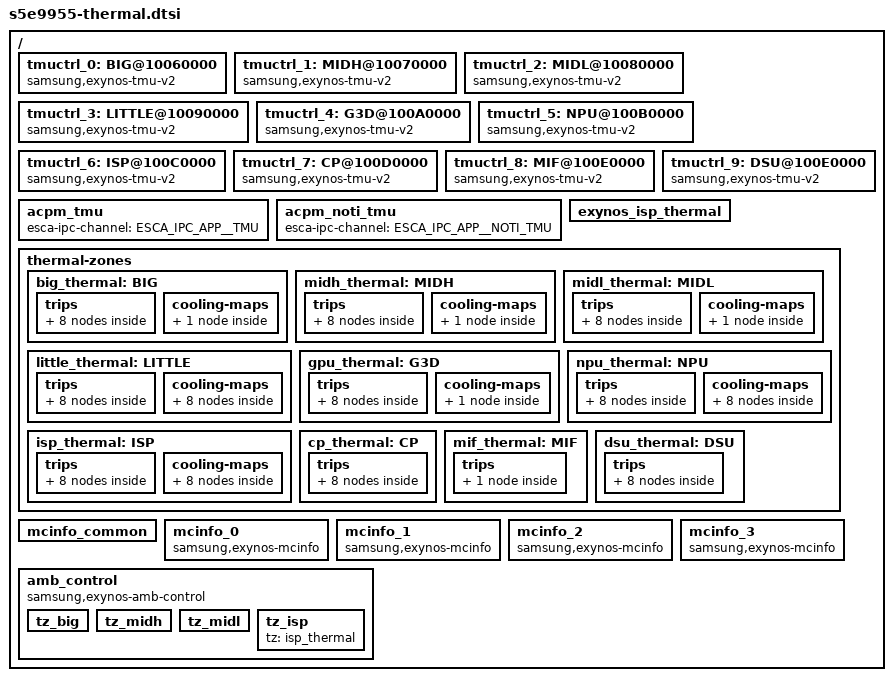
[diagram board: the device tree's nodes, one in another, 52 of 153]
/*
 * SAMSUNG EXYNOS9955 SoC DVFS Manager device tree source
 *
 * Copyright (c) 2024 Samsung Electronics Co., Ltd.
 *		http://www.samsung.com
 *
 * SAMSUNG EXYNOS9955 SoC device nodes are listed in this file.
 * EXYNOS based board files can include this file and provide
 * values for board specfic bindings.
 *
 * This program is free software; you can redistribute it and/or modify
 * it under the terms of the GNU General Public License version 2 as
 * published by the Free Software Foundation.
 */

/ {
	tmuctrl_0: BIG@10060000 {
		compatible = "samsung,exynos-tmu-v2";
		//reg = <0x0 0x10060000 0x800>;
		//interrupts = <GIC_SPI INTREQ__TMU_TMU_0 IRQ_TYPE_LEVEL_HIGH>;
		tmu_name = "BIG";
		id = <0>;
		hotplug_enable = <1>;
		hotplug_in_threshold = <91>;
		hotplug_out_threshold = <96>;
		cpu_domain = "9";
		#thermal-sensor-cells = <0>;
		//cal_id = <ACPM_DVFS_CPUCL3>;

		use-pi-thermal;
		polling_delay_on = <4>;
		polling_delay_off = <1000>;
		k_po = <0>;
		k_pu = <0>;
		k_i = <0>;
		i_max = <0>;
		integral_cutoff = <0>;
		sustainable_power = <0>;

		thermal_status_level = <80000 85000 90000>;
	};

	tmuctrl_1: MIDH@10070000 {
		compatible = "samsung,exynos-tmu-v2";
		//reg = <0x0 0x10070000 0x800>;
		//interrupts = <GIC_SPI INTREQ__TMU_TMU_1 IRQ_TYPE_LEVEL_HIGH>;
		tmu_name = "MIDH";
		hotplug_enable = <1>;
		hotplug_in_threshold = <91>;
		hotplug_out_threshold = <96>;
		cpu_domain = "7-8";
		id = <1>;
		#thermal-sensor-cells = <0>;
		//cal_id = <ACPM_DVFS_CPUCL2>;

		use-pi-thermal;
		polling_delay_on = <10>;
		polling_delay_off = <1000>;
		k_po = <0>;
		k_pu = <0>;
		k_i = <0>;
		i_max = <0>;
		integral_cutoff = <0>;
		sustainable_power = <0>;
	};

	tmuctrl_2: MIDL@10080000 {
		compatible = "samsung,exynos-tmu-v2";
		//reg = <0x0 0x10070000 0x800>;
		//interrupts = <GIC_SPI INTREQ__TMU_TMU_1 IRQ_TYPE_LEVEL_HIGH>;
		tmu_name = "MIDL";
		hotplug_enable = <1>;
		hotplug_in_threshold = <91>;
		hotplug_out_threshold = <96>;
		cpu_domain = "2-6";
		id = <2>;
		#thermal-sensor-cells = <0>;
		//cal_id = <ACPM_DVFS_CPUCL1>;

		use-pi-thermal;
		polling_delay_on = <10>;
		polling_delay_off = <1000>;
		k_po = <0>;
		k_pu = <0>;
		k_i = <0>;
		i_max = <0>;
		integral_cutoff = <0>;
		sustainable_power = <0>;
	};

	tmuctrl_3: LITTLE@10090000 {
		compatible = "samsung,exynos-tmu-v2";
		//reg = <0x0 0x10060000 0x800>;
		//interrupts = <GIC_SPI INTREQ__TMU_TMU_0 IRQ_TYPE_LEVEL_HIGH>;
		tmu_name = "LITTLE";
		id = <3>;
		#thermal-sensor-cells = <0>;
		polling_delay_on = <20>;
		polling_delay_off = <1000>;
	};

	tmuctrl_4: G3D@100A0000 {
		compatible = "samsung,exynos-tmu-v2";
		//reg = <0x0 0x10090000 0x800>;
		//interrupts = <GIC_SPI INTREQ__TMU_TMU_3 IRQ_TYPE_LEVEL_HIGH>;
		tmu_name = "G3D";
		id = <4>;
		#thermal-sensor-cells = <0>;

		use-pi-thermal;
		polling_delay_on = <10>;
		polling_delay_off = <1000>;
		k_po = <0>;
		k_pu = <0>;
		k_i = <0>;
		i_max = <0>;
		integral_cutoff = <0>;
		sustainable_power = <0>;
	};

	tmuctrl_5: NPU@100B0000 {
		compatible = "samsung,exynos-tmu-v2";
		//reg = <0x0 0x10080000 0x800>;
		//interrupts = <GIC_SPI INTREQ__TMU_TMU_2 IRQ_TYPE_LEVEL_HIGH>;
		tmu_name = "NPU";
		id = <5>;
		#thermal-sensor-cells = <0>;
	};

	tmuctrl_6: ISP@100C0000 {
		compatible = "samsung,exynos-tmu-v2";
		//reg = <0x0 0x10080000 0x800>;
		//interrupts = <GIC_SPI INTREQ__TMU_TMU_2 IRQ_TYPE_LEVEL_HIGH>;
		tmu_name = "ISP";
		id = <6>;
		#thermal-sensor-cells = <0>;
	};

	tmuctrl_7: CP@100D0000 {
		compatible = "samsung,exynos-tmu-v2";
		//reg = <0x0 0x10090000 0x800>;
		//interrupts = <GIC_SPI INTREQ__TMU_TMU_3 IRQ_TYPE_LEVEL_HIGH>;
		tmu_name = "CP";
		id = <7>;
		#thermal-sensor-cells = <0>;
	};

	tmuctrl_8: MIF@100E0000 {
		compatible = "samsung,exynos-tmu-v2";
		//reg = <0x0 0x10080000 0x800>;
		//interrupts = <GIC_SPI INTREQ__TMU_TMU_2 IRQ_TYPE_LEVEL_HIGH>;
		tmu_name = "MIF";
		id = <8>;
		#thermal-sensor-cells = <0>;
	};

	tmuctrl_9: DSU@100E0000 {
		compatible = "samsung,exynos-tmu-v2";
		//reg = <0x0 0x10080000 0x800>;
		//interrupts = <GIC_SPI INTREQ__TMU_TMU_2 IRQ_TYPE_LEVEL_HIGH>;
		tmu_name = "DSU";
		id = <9>;
		#thermal-sensor-cells = <0>;
	};

	acpm_tmu {
		esca-ipc-channel = <ESCA_IPC_APP__TMU>;
	};

	acpm_noti_tmu {
		esca-ipc-channel = <ESCA_IPC_APP__NOTI_TMU>;
	};

	exynos_isp_thermal: exynos_isp_thermal {
		#cooling-cells = <2>; /* min followed by max */
	};

	thermal-zones {
		big_thermal: BIG {
			zone_name  = "BIG_THERMAL";
			polling-delay-passive = <0>;
			polling-delay = <0>;
			thermal-sensors = <&tmuctrl_0>;

			trips {
				big_cold: big-cold {
					temperature = <20000>;
					hysteresis = <5000>; /* millicelsius */
					type = "active";
				};
				big_switch_on: big-switch-on {
					temperature = <60000>; /* millicelsius */
					hysteresis = <2000>; /* millicelsius */
					type = "active";
				};
				big_control_temp: big-control-temp {
					temperature = <70000>; /* millicelsius */
					hysteresis = <5000>; /* millicelsius */
					type = "passive";
				};
				big_alert0: big-alert0 {
					temperature = <95000>; /* millicelsius */
					hysteresis = <5000>; /* millicelsius */
					type = "active";
				};
				big_alert1: big-alert1 {
					temperature = <100000>; /* millicelsius */
					hysteresis = <5000>; /* millicelsius */
					type = "passive";
				};
				big_alert2: big-alert2 {
					temperature = <105000>; /* millicelsius */
					hysteresis = <5000>; /* millicelsius */
					type = "passive";
				};
				big_alert3: big-alert3 {
					temperature = <110000>; /* millicelsius */
					hysteresis = <5000>; /* millicelsius */
					type = "active";
				};
				big_hot: big-hot {
					temperature = <115000>; /* millicelsius */
					hysteresis = <5000>; /* millicelsius */
					type = "hot";
				};
			};
			cooling-maps {
				map0 {
					trip = <&big_control_temp>;
					cooling-device = <&cpufreq_domain3 0 0>;
				};
			};
		};

		midh_thermal: MIDH {
			zone_name  = "MIDH_THERMAL";
			polling-delay-passive = <0>;
			polling-delay = <0>;
			thermal-sensors = <&tmuctrl_1>;

			trips {
				midh_cold: midh-cold {
					temperature = <20000>;
					hysteresis = <5000>; /* millicelsius */
					type = "active";
				};
				midh_switch_on: midh-switch-on {
					temperature = <60000>; /* millicelsius */
					hysteresis = <2000>; /* millicelsius */
					type = "active";
				};
				midh_control_temp: midh-control-temp {
					temperature = <70000>; /* millicelsius */
					hysteresis = <5000>; /* millicelsius */
					type = "passive";
				};
				midh_alert0: midh-alert0 {
					temperature = <95000>; /* millicelsius */
					hysteresis = <5000>; /* millicelsius */
					type = "active";
				};
				midh_alert1: midh-alert1 {
					temperature = <100000>; /* millicelsius */
					hysteresis = <5000>; /* millicelsius */
					type = "passive";
				};
				midh_alert2: midh-alert2 {
					temperature = <105000>; /* millicelsius */
					hysteresis = <5000>; /* millicelsius */
					type = "passive";
				};
				midh_alert3: midh-alert3 {
					temperature = <110000>; /* millicelsius */
					hysteresis = <5000>; /* millicelsius */
					type = "active";
				};
				midh_hot: midh-hot {
					temperature = <115000>; /* millicelsius */
					hysteresis = <5000>; /* millicelsius */
					type = "hot";
				};
			};

			cooling-maps {
				map0 {
					trip = <&midh_control_temp>;
					cooling-device = <&cpufreq_domain2 0 0>;
				};
			};
		};

		midl_thermal: MIDL {
			zone_name  = "MIDL_THERMAL";
			polling-delay-passive = <0>;
			polling-delay = <0>;
			thermal-sensors = <&tmuctrl_2>;

			trips {
				midl_cold: midl-cold {
					temperature = <20000>;
					hysteresis = <5000>; /* millicelsius */
					type = "active";
				};
				midl_switch_on: midl-switch-on {
					temperature = <60000>; /* millicelsius */
					hysteresis = <2000>; /* millicelsius */
					type = "active";
				};
				midl_control_temp: midl-control-temp {
					temperature = <70000>; /* millicelsius */
					hysteresis = <5000>; /* millicelsius */
					type = "passive";
				};
				midl_alert0: midl-alert0 {
					temperature = <95000>; /* millicelsius */
					hysteresis = <5000>; /* millicelsius */
					type = "active";
				};
				midl_alert1: midl-alert1 {
					temperature = <100000>; /* millicelsius */
					hysteresis = <5000>; /* millicelsius */
					type = "passive";
				};
				midl_alert2: midl-alert2 {
					temperature = <105000>; /* millicelsius */
					hysteresis = <5000>; /* millicelsius */
					type = "passive";
				};
				midl_alert3: midl-alert3 {
					temperature = <110000>; /* millicelsius */
					hysteresis = <5000>; /* millicelsius */
					type = "active";
				};
				midl_hot: midl-hot {
					temperature = <115000>; /* millicelsius */
					hysteresis = <5000>; /* millicelsius */
					type = "hot";
				};
			};

			cooling-maps {
				map0 {
					trip = <&midl_control_temp>;
					cooling-device = <&cpufreq_domain1 0 0>;
				};
			};
		};

		little_thermal: LITTLE {
			zone_name  = "LITTLE_THERMAL";
			polling-delay-passive = <0>;
			polling-delay = <0>;
			thermal-sensors = <&tmuctrl_3>;

			trips {
				lit_alert0: lit-alert0 {
					temperature = <30000>; /* millicelsius */
					hysteresis = <5000>; /* millicelsius */
					type = "active";
				};
				lit_alert1: lit-alert1 {
					temperature = <90000>; /* millicelsius */
					hysteresis = <5000>; /* millicelsius */
					type = "active";
				};
				lit_alert2: lit-alert2 {
					temperature = <91000>; /* millicelsius */
					hysteresis = <5000>; /* millicelsius */
					type = "passive";
				};
				lit_alert3: lit-alert3 {
					temperature = <92000>; /* millicelsius */
					hysteresis = <5000>; /* millicelsius */
					type = "passive";
				};
				lit_alert4: lit-alert4 {
					temperature = <93000>; /* millicelsius */
					hysteresis = <5000>; /* millicelsius */
					type = "passive";
				};
				lit_alert5: lit-alert5 {
					temperature = <94000>; /* millicelsius */
					hysteresis = <5000>; /* millicelsius */
					type = "passive";
				};
				lit_alert6: lit-alert6 {
					temperature = <115000>; /* millicelsius */
					hysteresis = <5000>; /* millicelsius */
					type = "active";
				};
				lit_hot: lit-hot {
					temperature = <125000>; /* millicelsius */
					hysteresis = <5000>; /* millicelsius */
					type = "hot";
				};
			};

			cooling-maps {
				map0 {
					trip = <&lit_alert0>;
					cooling-device = <&cpufreq_domain0 0 0>;
				};
				map1 {
					trip = <&lit_alert1>;
					cooling-device = <&cpufreq_domain0 0 0>;
				};
				map2 {
					trip = <&lit_alert2>;
					cooling-device = <&cpufreq_domain0 0 0>;
				};
				map3 {
					trip = <&lit_alert3>;
					cooling-device = <&cpufreq_domain0 0 0>;
				};
				map4 {
					trip = <&lit_alert4>;
					cooling-device = <&cpufreq_domain0 0 0>;
				};
				map5 {
					trip = <&lit_alert5>;
					cooling-device = <&cpufreq_domain0 0 0>;
				};
				map6 {
					trip = <&lit_alert6>;
					cooling-device = <&cpufreq_domain0 0 0>;
				};
				map7 {
					trip = <&lit_hot>;
					cooling-device = <&cpufreq_domain0 0 0>;
				};
			};
		};

		gpu_thermal: G3D {
			zone_name  = "G3D_THERMAL";
			polling-delay-passive = <0>;
			polling-delay = <0>;
			thermal-sensors = <&tmuctrl_4>;

			trips {
				gpu_cold: gpu-cold {
					temperature = <20000>;
					hysteresis = <5000>; /* millicelsius */
					type = "active";
				};
				gpu_switch_on: gpu-switch-on {
					temperature = <65000>; /* millicelsius */
					hysteresis = <2000>; /* millicelsius */
					type = "active";
				};
				gpu_control_temp: gpu-control-temp {
					temperature = <70000>; /* millicelsius */
					hysteresis = <5000>; /* millicelsius */
					type = "passive";
				};
				gpu_alert0: gpu-alert0 {
					temperature = <95000>; /* millicelsius */
					hysteresis = <5000>; /* millicelsius */
					type = "active";
				};
				gpu_alert1: gpu-alert1 {
					temperature = <100000>; /* millicelsius */
					hysteresis = <5000>; /* millicelsius */
					type = "passive";
				};
				gpu_alert2: gpu-alert2 {
					temperature = <105000>; /* millicelsius */
					hysteresis = <5000>; /* millicelsius */
					type = "passive";
				};
				gpu_alert3: gpu-alert3 {
					temperature = <110000>; /* millicelsius */
					hysteresis = <5000>; /* millicelsius */
					type = "active";
				};
				gpu_hot: gpu-hot {
					temperature = <115000>; /* millicelsius */
					hysteresis = <5000>; /* millicelsius */
					type = "hot";
				};
			};

			cooling-maps {
				map0 {
					trip = <&gpu_control_temp>;
					cooling-device = <&sgpu 0 0>;
				};
			};
		};
		npu_thermal: NPU {
			zone_name  = "NPU_THERMAL";
			polling-delay-passive = <0>;
			polling-delay = <0>;
			thermal-sensors = <&tmuctrl_5>;

			trips {
				npu_alert0: npu-alert0 {
					temperature = <20000>; /* millicelsius */
					hysteresis = <5000>; /* millicelsius */
					type = "active";
				};
				npu_alert1: npu-alert1 {
					temperature = <76000>; /* millicelsius */
					hysteresis = <5000>; /* millicelsius */
					type = "active";
				};
				npu_alert2: npu-alert2 {
					temperature = <81000>; /* millicelsius */
					hysteresis = <5000>; /* millicelsius */
					type = "active";
				};
				npu_alert3: npu-alert3 {
					temperature = <86000>; /* millicelsius */
					hysteresis = <5000>; /* millicelsius */
					type = "active";
				};
				npu_alert4: npu-alert4 {
					temperature = <91000>; /* millicelsius */
					hysteresis = <5000>; /* millicelsius */
					type = "active";
				};
				npu_alert5: npu-alert5 {
					temperature = <96000>; /* millicelsius */
					hysteresis = <5000>; /* millicelsius */
					type = "active";
				};
				npu_alert6: npu-alert6 {
					temperature = <101000>; /* millicelsius */
					hysteresis = <5000>; /* millicelsius */
					type = "active";
				};
				npu_hot: npu-hot {
					temperature = <115000>; /* millicelsius */
					hysteresis = <5000>; /* millicelsius */
					type = "hot";
				};
			};

			cooling-maps {
				map0 {
					trip = <&npu_alert0>;
					cooling-device = <&devfreq_2 0 0>;
				};
				map1 {
					trip = <&npu_alert1>;
					cooling-device = <&devfreq_2 0 0>;
				};
				map2 {
					trip = <&npu_alert2>;
					cooling-device = <&devfreq_2 0 0>;
				};
				map3 {
					trip = <&npu_alert3>;
					cooling-device = <&devfreq_2 0 0>;
				};
				map4 {
					trip = <&npu_alert4>;
					cooling-device = <&devfreq_2 0 0>;
				};
				map5 {
					trip = <&npu_alert5>;
					cooling-device = <&devfreq_2 0 0>;
				};
				map6 {
					trip = <&npu_alert6>;
					cooling-device = <&devfreq_2 0 0>;
				};
				map7 {
					trip = <&npu_hot>;
					cooling-device = <&devfreq_2 0 0>;
				};
			};
		};

		isp_thermal: ISP {
			zone_name  = "ISP_THERMAL";
			polling-delay-passive = <0>;
			polling-delay = <0>;
			thermal-sensors = <&tmuctrl_6>;

			trips {
				isp_alert0: isp-alert0 {
					temperature = <20000>; /* millicelsius */
					hysteresis = <5000>; /* millicelsius */
					type = "active";
				};
				isp_alert1: isp-alert1 {
					temperature = <95000>; /* millicelsius */
					hysteresis = <5000>; /* millicelsius */
					type = "active";
				};
				isp_alert2: isp-alert2 {
					temperature = <100000>; /* millicelsius */
					hysteresis = <5000>; /* millicelsius */
					type = "active";
				};
				isp_alert3: isp-alert3 {
					temperature = <105000>; /* millicelsius */
					hysteresis = <5000>; /* millicelsius */
					type = "active";
				};
				isp_alert4: isp-alert4 {
					temperature = <110000>; /* millicelsius */
					hysteresis = <5000>; /* millicelsius */
					type = "active";
				};
				isp_alert5: isp-alert5 {
					temperature = <115000>; /* millicelsius */
					hysteresis = <5000>; /* millicelsius */
					type = "active";
				};
				isp_alert6: isp-alert6 {
					temperature = <115000>; /* millicelsius */
					hysteresis = <5000>; /* millicelsius */
					type = "active";
				};
				isp_hot: isp-hot {
					temperature = <115000>; /* millicelsius */
					hysteresis = <5000>; /* millicelsius */
					type = "hot";
				};
			};

			cooling-maps {
				map0 {
					trip = <&isp_alert0>;
					cooling-device = <&exynos_isp_thermal 0 0>;
				};
				map1 {
					trip = <&isp_alert1>;
					cooling-device = <&exynos_isp_thermal 0 0>;
				};
				map2 {
					trip = <&isp_alert2>;
					cooling-device = <&exynos_isp_thermal 0 0>;
				};
				map3 {
					trip = <&isp_alert3>;
					cooling-device = <&exynos_isp_thermal 0 0>;
				};
				map4 {
					trip = <&isp_alert4>;
					cooling-device = <&exynos_isp_thermal 0 0>;
				};
				map5 {
					trip = <&isp_alert5>;
					cooling-device = <&exynos_isp_thermal 0 0>;
				};
				map6 {
					trip = <&isp_alert6>;
					cooling-device = <&exynos_isp_thermal 0 0>;
				};
				map7 {
					trip = <&isp_hot>;
					cooling-device = <&exynos_isp_thermal 0 0>;
				};
			};
		};

		cp_thermal: CP {
			zone_name = "CP_THERMAL";
			polling-delay-passive = <0>;
			polling-delay = <0>;
			thermal-sensors = <&tmuctrl_7>;

			trips {
				cp_alert0: cp-alert0 {
					temperature = <30000>; /* millicelsius */
					hysteresis = <5000>; /* millicelsius */
					type = "active";
				};
				cp_alert1: cp-alert1 {
					temperature = <125000>; /* millicelsius */
					hysteresis = <5000>; /* millicelsius */
					type = "passive";
				};
				cp_alert2: cp-alert2 {
					temperature = <125000>; /* millicelsius */
					hysteresis = <5000>; /* millicelsius */
					type = "passive";
				};
				cp_alert3: cp-alert3 {
					temperature = <125000>; /* millicelsius */
					hysteresis = <5000>; /* millicelsius */
					type = "passive";
				};
				cp_alert4: cp-alert4 {
					temperature = <125000>; /* millicelsius */
					hysteresis = <5000>; /* millicelsius */
					type = "passive";
				};
				cp_alert5: cp-alert5 {
					temperature = <125000>; /* millicelsius */
					hysteresis = <5000>; /* millicelsius */
					type = "passive";
				};
				cp_alert6: cp-alert6 {
					temperature = <125000>; /* millicelsius */
					hysteresis = <5000>; /* millicelsius */
					type = "passive";
				};
				cp_hot: cp-hot {
					temperature = <125000>; /* millicelsius */
					hysteresis = <5000>; /* millicelsius */
					type = "hot";
				};
			};
		};

		mif_thermal: MIF {
			zone_name = "MIF_THERMAL";
			polling-delay-passive = <0>;
			polling-delay = <0>;
			thermal-sensors = <&tmuctrl_8>;
			trips {
				mif_alert0: mif-alert0 {
					temperature = <0>; /* millicelsius */
					hysteresis = <0>; /* millicelsius */
					type = "passive";
				};
			};
		};

		dsu_thermal: DSU {
			zone_name = "DSU_THERMAL";
			polling-delay-passive = <0>;
			polling-delay = <0>;
			thermal-sensors = <&tmuctrl_9>;
			trips {
				dsu_alert0: dsu-alert0 {
					temperature = <125000>; /* millicelsius */
					hysteresis = <5000>; /* millicelsius */
					type = "passive";
				};
				dsu_alert1: dsu-alert1 {
					temperature = <125000>; /* millicelsius */
					hysteresis = <5000>; /* millicelsius */
					type = "passive";
				};
				dsu_alert2: dsu-alert2 {
					temperature = <125000>; /* millicelsius */
					hysteresis = <5000>; /* millicelsius */
					type = "passive";
				};
				dsu_alert3: dsu-alert3 {
					temperature = <125000>; /* millicelsius */
					hysteresis = <5000>; /* millicelsius */
					type = "passive";
				};
				dsu_alert4: dsu-alert4 {
					temperature = <125000>; /* millicelsius */
					hysteresis = <5000>; /* millicelsius */
					type = "passive";
				};
				dsu_alert5: dsu-alert5 {
					temperature = <125000>; /* millicelsius */
					hysteresis = <5000>; /* millicelsius */
					type = "passive";
				};
				dsu_alert6: dsu-alert6 {
					temperature = <125000>; /* millicelsius */
					hysteresis = <5000>; /* millicelsius */
					type = "passive";
				};
				dsu_hot: dsu-hot {
					temperature = <125000>; /* millicelsius */
					hysteresis = <5000>; /* millicelsius */
					type = "hot";
				};
			};
		};
	};

	mcinfo_common {
		bit_field = <24 5>;
		/* start bit, width */
		hotplug_cond = <0xc>;
		hotplug_cpu_list = "2-9";
	};
	mcinfo_0 {
		compatible = "samsung,exynos-mcinfo";
		reg = <0x0 0x2D03F04C 0x4>;
		interrupts = <GIC_SPI INTREQ__DMC_TEMPERR_MIF0 IRQ_TYPE_LEVEL_HIGH>,
			<GIC_SPI INTREQ__DMC_TEMPHOT_MIF0 IRQ_TYPE_LEVEL_HIGH>;
	};
	mcinfo_1 {
		compatible = "samsung,exynos-mcinfo";
		reg = <0x0 0x2D23F04C 0x4>;
		interrupts = <GIC_SPI INTREQ__DMC_TEMPERR_MIF1 IRQ_TYPE_LEVEL_HIGH>,
			<GIC_SPI INTREQ__DMC_TEMPHOT_MIF1 IRQ_TYPE_LEVEL_HIGH>;
	};
	mcinfo_2 {
		compatible = "samsung,exynos-mcinfo";
		reg = <0x0 0x2D43F04C 0x4>;
		interrupts = <GIC_SPI INTREQ__DMC_TEMPERR_MIF2 IRQ_TYPE_LEVEL_HIGH>,
			<GIC_SPI INTREQ__DMC_TEMPHOT_MIF2 IRQ_TYPE_LEVEL_HIGH>;
	};
	mcinfo_3 {
		compatible = "samsung,exynos-mcinfo";
		reg = <0x0 0x2D63F04C 0x4>;
		interrupts = <GIC_SPI INTREQ__DMC_TEMPERR_MIF3 IRQ_TYPE_LEVEL_HIGH>,
			<GIC_SPI INTREQ__DMC_TEMPHOT_MIF3 IRQ_TYPE_LEVEL_HIGH>;
	};

	amb_control {
		compatible = "samsung,exynos-amb-control";

		amb_tz_name = "battery";

		default_sampling_rate = <1000>;
		high_sampling_rate = <100>;
		amb_switch_on = <55000>;

		mcinfo_threshold = <60000>;

		use_mif_throttle;
		mif_down_threshold = <60000>;
		mif_up_threshold = <55000>;
		mif_throttle_freq = <2028000>;

		mif_tz_name = "MIF";
		mif_hot_switch_on = <95000>;
		mif_hot_on_threshold = <105000>;
		mif_hot_off_threshold = <95000>;
		mif_hot_throttle_freq = <3172000>;

		tz_big {
			tz = <&big_thermal>;

			hotplug_cpu_list = "9";
			hotplug_in_threshold = <60000>;
			hotplug_out_threshold = <65000>;
		};

		tz_midh {
			tz = <&midh_thermal>;

			hotplug_cpu_list = "7-8";
			hotplug_in_threshold = <60000>;
			hotplug_out_threshold = <65000>;
		};

		tz_midl {
			tz = <&midl_thermal>;

			hotplug_cpu_list = "2-6";
			hotplug_in_threshold = <60000>;
			hotplug_out_threshold = <65000>;
		};

		tz_isp {
			tz = <&isp_thermal>;
		};
	};
};
